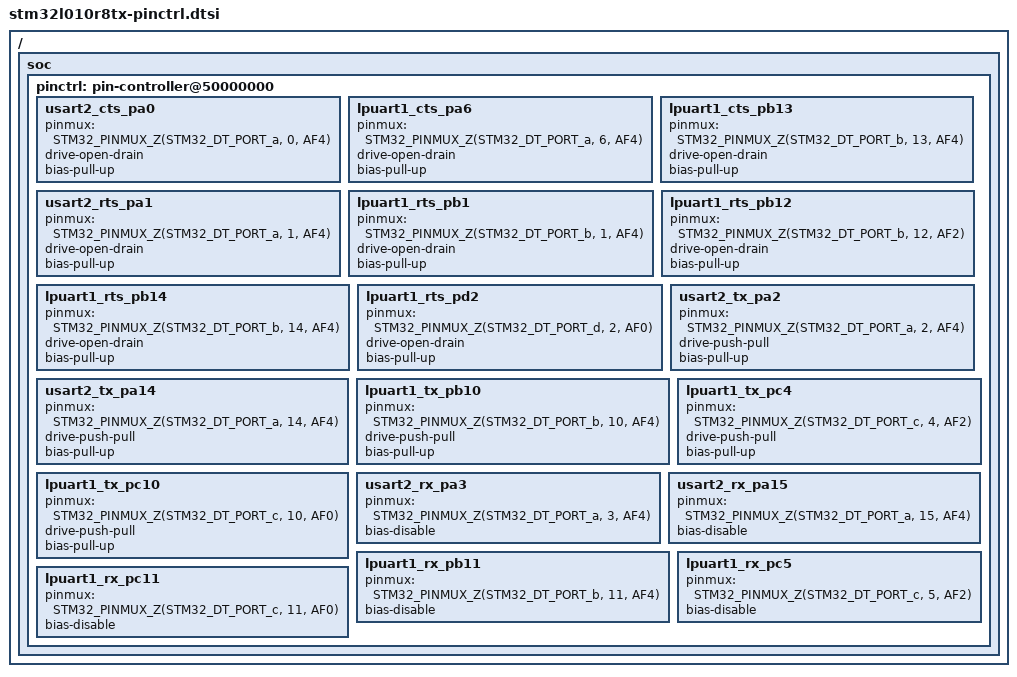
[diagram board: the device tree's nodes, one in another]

/*
 * NOTE: Autogenerated file using stm32_pinctrl_gen.py
 *
 * SPDX-License-Identifier: Apache-2.0
 */

#include <dt-bindings/pinctrl/stm32-pinctrl.h>

/ {
	soc {
		pinctrl: pin-controller@50000000 {
			/* UART_CTS */
			usart2_cts_pa0: usart2_cts_pa0 {
				pinmux = <STM32_PINMUX_Z(STM32_DT_PORT_a, 0, AF4)>;
				drive-open-drain;
				bias-pull-up;
			};

			lpuart1_cts_pa6: lpuart1_cts_pa6 {
				pinmux = <STM32_PINMUX_Z(STM32_DT_PORT_a, 6, AF4)>;
				drive-open-drain;
				bias-pull-up;
			};

			lpuart1_cts_pa6: lpuart1_cts_pa6 {
				pinmux = <STM32_PINMUX_Z(STM32_DT_PORT_a, 6, AF4)>;
				drive-open-drain;
				bias-pull-up;
			};

			lpuart1_cts_pb13: lpuart1_cts_pb13 {
				pinmux = <STM32_PINMUX_Z(STM32_DT_PORT_b, 13, AF4)>;
				drive-open-drain;
				bias-pull-up;
			};

			lpuart1_cts_pb13: lpuart1_cts_pb13 {
				pinmux = <STM32_PINMUX_Z(STM32_DT_PORT_b, 13, AF4)>;
				drive-open-drain;
				bias-pull-up;
			};


			/* UART_RTS */
			usart2_rts_pa1: usart2_rts_pa1 {
				pinmux = <STM32_PINMUX_Z(STM32_DT_PORT_a, 1, AF4)>;
				drive-open-drain;
				bias-pull-up;
			};

			lpuart1_rts_pb1: lpuart1_rts_pb1 {
				pinmux = <STM32_PINMUX_Z(STM32_DT_PORT_b, 1, AF4)>;
				drive-open-drain;
				bias-pull-up;
			};

			lpuart1_rts_pb1: lpuart1_rts_pb1 {
				pinmux = <STM32_PINMUX_Z(STM32_DT_PORT_b, 1, AF4)>;
				drive-open-drain;
				bias-pull-up;
			};

			lpuart1_rts_pb12: lpuart1_rts_pb12 {
				pinmux = <STM32_PINMUX_Z(STM32_DT_PORT_b, 12, AF2)>;
				drive-open-drain;
				bias-pull-up;
			};

			lpuart1_rts_pb12: lpuart1_rts_pb12 {
				pinmux = <STM32_PINMUX_Z(STM32_DT_PORT_b, 12, AF2)>;
				drive-open-drain;
				bias-pull-up;
			};

			lpuart1_rts_pb14: lpuart1_rts_pb14 {
				pinmux = <STM32_PINMUX_Z(STM32_DT_PORT_b, 14, AF4)>;
				drive-open-drain;
				bias-pull-up;
			};

			lpuart1_rts_pb14: lpuart1_rts_pb14 {
				pinmux = <STM32_PINMUX_Z(STM32_DT_PORT_b, 14, AF4)>;
				drive-open-drain;
				bias-pull-up;
			};

			lpuart1_rts_pd2: lpuart1_rts_pd2 {
				pinmux = <STM32_PINMUX_Z(STM32_DT_PORT_d, 2, AF0)>;
				drive-open-drain;
				bias-pull-up;
			};

			lpuart1_rts_pd2: lpuart1_rts_pd2 {
				pinmux = <STM32_PINMUX_Z(STM32_DT_PORT_d, 2, AF0)>;
				drive-open-drain;
				bias-pull-up;
			};


			/* UART_TX */
			usart2_tx_pa2: usart2_tx_pa2 {
				pinmux = <STM32_PINMUX_Z(STM32_DT_PORT_a, 2, AF4)>;
				drive-push-pull;
				bias-pull-up;
			};

			usart2_tx_pa14: usart2_tx_pa14 {
				pinmux = <STM32_PINMUX_Z(STM32_DT_PORT_a, 14, AF4)>;
				drive-push-pull;
				bias-pull-up;
			};

			lpuart1_tx_pb10: lpuart1_tx_pb10 {
				pinmux = <STM32_PINMUX_Z(STM32_DT_PORT_b, 10, AF4)>;
				drive-push-pull;
				bias-pull-up;
			};

			lpuart1_tx_pb10: lpuart1_tx_pb10 {
				pinmux = <STM32_PINMUX_Z(STM32_DT_PORT_b, 10, AF4)>;
				drive-push-pull;
				bias-pull-up;
			};

			lpuart1_tx_pc4: lpuart1_tx_pc4 {
				pinmux = <STM32_PINMUX_Z(STM32_DT_PORT_c, 4, AF2)>;
				drive-push-pull;
				bias-pull-up;
			};

			lpuart1_tx_pc4: lpuart1_tx_pc4 {
				pinmux = <STM32_PINMUX_Z(STM32_DT_PORT_c, 4, AF2)>;
				drive-push-pull;
				bias-pull-up;
			};

			lpuart1_tx_pc10: lpuart1_tx_pc10 {
				pinmux = <STM32_PINMUX_Z(STM32_DT_PORT_c, 10, AF0)>;
				drive-push-pull;
				bias-pull-up;
			};

			lpuart1_tx_pc10: lpuart1_tx_pc10 {
				pinmux = <STM32_PINMUX_Z(STM32_DT_PORT_c, 10, AF0)>;
				drive-push-pull;
				bias-pull-up;
			};


			/* UART_RX */
			usart2_rx_pa3: usart2_rx_pa3 {
				pinmux = <STM32_PINMUX_Z(STM32_DT_PORT_a, 3, AF4)>;
				bias-disable;
			};

			usart2_rx_pa15: usart2_rx_pa15 {
				pinmux = <STM32_PINMUX_Z(STM32_DT_PORT_a, 15, AF4)>;
				bias-disable;
			};

			lpuart1_rx_pb11: lpuart1_rx_pb11 {
				pinmux = <STM32_PINMUX_Z(STM32_DT_PORT_b, 11, AF4)>;
				bias-disable;
			};

			lpuart1_rx_pb11: lpuart1_rx_pb11 {
				pinmux = <STM32_PINMUX_Z(STM32_DT_PORT_b, 11, AF4)>;
				bias-disable;
			};

			lpuart1_rx_pc5: lpuart1_rx_pc5 {
				pinmux = <STM32_PINMUX_Z(STM32_DT_PORT_c, 5, AF2)>;
				bias-disable;
			};

			lpuart1_rx_pc5: lpuart1_rx_pc5 {
				pinmux = <STM32_PINMUX_Z(STM32_DT_PORT_c, 5, AF2)>;
				bias-disable;
			};

			lpuart1_rx_pc11: lpuart1_rx_pc11 {
				pinmux = <STM32_PINMUX_Z(STM32_DT_PORT_c, 11, AF0)>;
				bias-disable;
			};

			lpuart1_rx_pc11: lpuart1_rx_pc11 {
				pinmux = <STM32_PINMUX_Z(STM32_DT_PORT_c, 11, AF0)>;
				bias-disable;
			};

		};
	};
};
